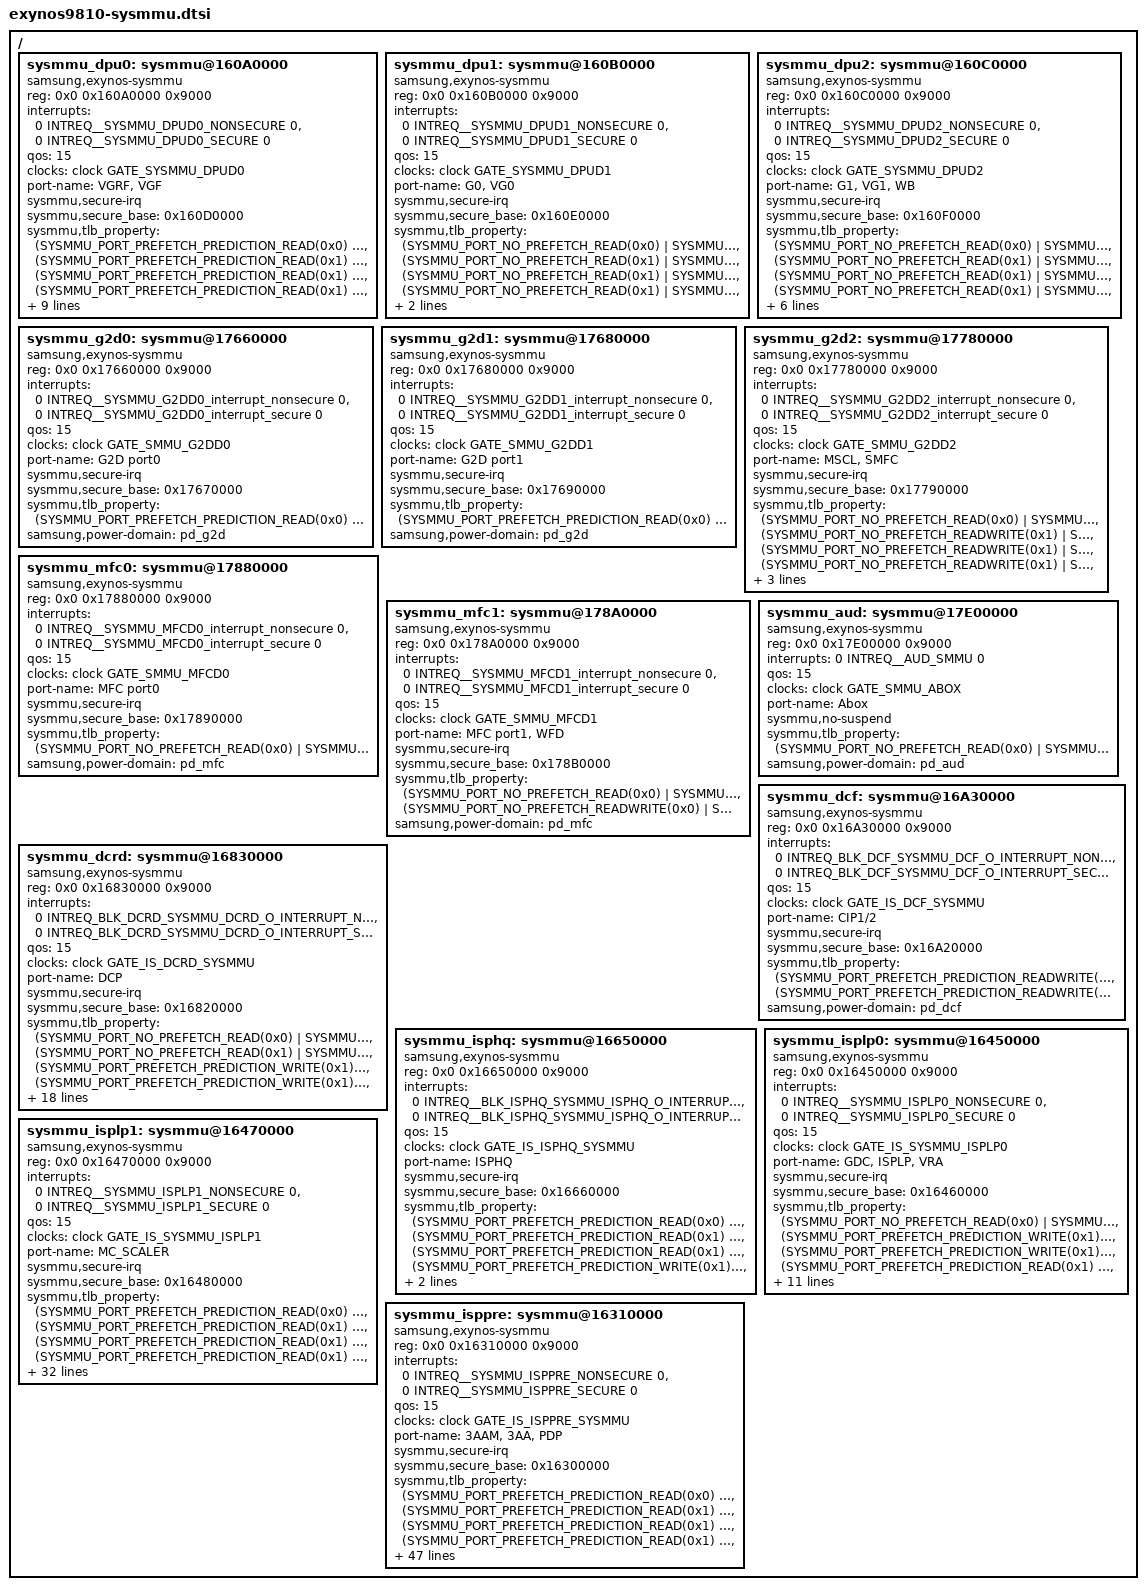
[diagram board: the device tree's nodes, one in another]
/*
 * SAMSUNG EXYNOS9810 SoC device tree source
 *
 * Copyright (c) 2018 Samsung Electronics Co., Ltd.
 *		http://www.samsung.com
 *
 * SAMSUNG EXYNOS9810 SoC device nodes are listed in this file.
 * EXYNOS9810 based board files can include this file and provide
 * values for board specfic bindings.
 *
 * This program is free software; you can redistribute it and/or modify
 * it under the terms of the GNU General Public License version 2 as
 * published by the Free Software Foundation.
 */

#include <dt-bindings/clock/exynos9810.h>
#include <dt-bindings/interrupt-controller/arm-gic.h>
#include <dt-bindings/sysmmu/sysmmu.h>

/ {
	sysmmu_dpu0: sysmmu@160A0000 {
		compatible = "samsung,exynos-sysmmu";
		reg = <0x0 0x160A0000 0x9000>;
		interrupts = <0 INTREQ__SYSMMU_DPUD0_NONSECURE 0>,
			     <0 INTREQ__SYSMMU_DPUD0_SECURE 0>;
		qos = <15>;
		clock-names = "aclk";
		clocks = <&clock GATE_SYSMMU_DPUD0>;
		port-name = "VGRF, VGF";
		sysmmu,secure-irq;
		sysmmu,secure_base = <0x160D0000>;
		sysmmu,tlb_property =
			<(SYSMMU_PORT_PREFETCH_PREDICTION_READ(0x0) | SYSMMU_BL4) SYSMMU_NOID>,
			<(SYSMMU_PORT_PREFETCH_PREDICTION_READ(0x1) | SYSMMU_BL4) SYSMMU_ID_MASK(0x5, 0xF)>,
			<(SYSMMU_PORT_PREFETCH_PREDICTION_READ(0x1) | SYSMMU_BL4) SYSMMU_ID_MASK(0x6, 0xF)>,
			<(SYSMMU_PORT_PREFETCH_PREDICTION_READ(0x1) | SYSMMU_BL4) SYSMMU_ID_MASK(0x7, 0xF)>,
			<(SYSMMU_PORT_PREFETCH_PREDICTION_READ(0x1) | SYSMMU_BL4) SYSMMU_ID_MASK(0xC, 0xF)>,
			<(SYSMMU_PORT_PREFETCH_PREDICTION_READ(0x1) | SYSMMU_BL4) SYSMMU_ID_MASK(0xD, 0xF)>,
			<(SYSMMU_PORT_PREFETCH_PREDICTION_READ(0x1) | SYSMMU_BL4) SYSMMU_ID_MASK(0x0, 0xF)>,
			<(SYSMMU_PORT_PREFETCH_PREDICTION_READ(0x1) | SYSMMU_BL4) SYSMMU_ID_MASK(0x1, 0xF)>,
			<(SYSMMU_PORT_PREFETCH_PREDICTION_READ(0x1) | SYSMMU_BL4) SYSMMU_ID_MASK(0x2, 0xF)>,
			<(SYSMMU_PORT_PREFETCH_PREDICTION_READ(0x1) | SYSMMU_BL4) SYSMMU_ID_MASK(0x3, 0xF)>,
			<(SYSMMU_PORT_PREFETCH_PREDICTION_READ(0x1) | SYSMMU_BL4) SYSMMU_ID_MASK(0x8, 0xF)>,
			<(SYSMMU_PORT_PREFETCH_PREDICTION_READ(0x1) | SYSMMU_BL4) SYSMMU_ID_MASK(0x9, 0xF)>;
		#iommu-cells = <0>;
		samsung,power-domain = <&pd_dpu>;
	};

	sysmmu_dpu1: sysmmu@160B0000 {
		compatible = "samsung,exynos-sysmmu";
		reg = <0x0 0x160B0000 0x9000>;
		interrupts = <0 INTREQ__SYSMMU_DPUD1_NONSECURE 0>,
			     <0 INTREQ__SYSMMU_DPUD1_SECURE 0>;
		qos = <15>;
		clock-names = "aclk";
		clocks = <&clock GATE_SYSMMU_DPUD1>;
		port-name = "G0, VG0";
		sysmmu,secure-irq;
		sysmmu,secure_base = <0x160E0000>;
		sysmmu,tlb_property =
			<(SYSMMU_PORT_NO_PREFETCH_READ(0x0) | SYSMMU_BL1) SYSMMU_NOID>,
			<(SYSMMU_PORT_NO_PREFETCH_READ(0x1) | SYSMMU_BL1) SYSMMU_ID_MASK(0x2, 0xF)>,
			<(SYSMMU_PORT_NO_PREFETCH_READ(0x1) | SYSMMU_BL1) SYSMMU_ID_MASK(0x3, 0xF)>,
			<(SYSMMU_PORT_NO_PREFETCH_READ(0x1) | SYSMMU_BL1) SYSMMU_ID_MASK(0x4, 0xF)>,
			<(SYSMMU_PORT_NO_PREFETCH_READ(0x1) | SYSMMU_BL1) SYSMMU_ID_MASK(0x5, 0xF)>;
		#iommu-cells = <0>;
		samsung,power-domain = <&pd_dpu>;
	};

	sysmmu_dpu2: sysmmu@160C0000 {
		compatible = "samsung,exynos-sysmmu";
		reg = <0x0 0x160C0000 0x9000>;
		interrupts = <0 INTREQ__SYSMMU_DPUD2_NONSECURE 0>,
			     <0 INTREQ__SYSMMU_DPUD2_SECURE 0>;
		qos = <15>;
		clock-names = "aclk";
		clocks = <&clock GATE_SYSMMU_DPUD2>;
		port-name = "G1, VG1, WB";
		sysmmu,secure-irq;
		sysmmu,secure_base = <0x160F0000>;
		sysmmu,tlb_property =
			<(SYSMMU_PORT_NO_PREFETCH_READ(0x0)  | SYSMMU_BL1) SYSMMU_NOID>,
			<(SYSMMU_PORT_NO_PREFETCH_READ(0x1)  | SYSMMU_BL1) SYSMMU_ID_MASK(0x2, 0xF)>,
			<(SYSMMU_PORT_NO_PREFETCH_READ(0x1)  | SYSMMU_BL1) SYSMMU_ID_MASK(0x3, 0xF)>,
			<(SYSMMU_PORT_NO_PREFETCH_READ(0x1)  | SYSMMU_BL1) SYSMMU_ID_MASK(0x4, 0xF)>,
			<(SYSMMU_PORT_NO_PREFETCH_READ(0x1)  | SYSMMU_BL1) SYSMMU_ID_MASK(0x5, 0xF)>,
			<(SYSMMU_PORT_NO_PREFETCH_WRITE(0x1) | SYSMMU_BL1) SYSMMU_ID_MASK(0x0, 0x18)>,
			<(SYSMMU_PORT_NO_PREFETCH_WRITE(0x1) | SYSMMU_BL1) SYSMMU_ID_MASK(0x8, 0x18)>,
			<(SYSMMU_PORT_NO_PREFETCH_WRITE(0x1) | SYSMMU_BL1) SYSMMU_ID_MASK(0x10, 0x18)>,
			<(SYSMMU_PORT_NO_PREFETCH_WRITE(0x1) | SYSMMU_BL1) SYSMMU_ID_MASK(0x18, 0x18)>;
		#iommu-cells = <0>;
		samsung,power-domain = <&pd_dpu>;
	};

	sysmmu_g2d0: sysmmu@17660000 {
		compatible = "samsung,exynos-sysmmu";
		reg = <0x0 0x17660000 0x9000>;
		interrupts = <0 INTREQ__SYSMMU_G2DD0_interrupt_nonsecure 0>,
			     <0 INTREQ__SYSMMU_G2DD0_interrupt_secure 0>;
		qos = <15>;
		clock-names = "aclk";
		clocks = <&clock GATE_SMMU_G2DD0>;
		port-name = "G2D port0";
		sysmmu,secure-irq;
		sysmmu,secure_base = <0x17670000>;
		sysmmu,tlb_property =
			<(SYSMMU_PORT_PREFETCH_PREDICTION_READ(0x0) | SYSMMU_BL32) SYSMMU_NOID>;
		#iommu-cells = <0>;
		samsung,power-domain = <&pd_g2d>;
	};

	sysmmu_g2d1: sysmmu@17680000 {
		compatible = "samsung,exynos-sysmmu";
		reg = <0x0 0x17680000 0x9000>;
		interrupts = <0 INTREQ__SYSMMU_G2DD1_interrupt_nonsecure 0>,
			     <0 INTREQ__SYSMMU_G2DD1_interrupt_secure 0>;
		qos = <15>;
		clock-names = "aclk";
		clocks = <&clock GATE_SMMU_G2DD1>;
		port-name = "G2D port1";
		sysmmu,secure-irq;
		sysmmu,secure_base = <0x17690000>;
		sysmmu,tlb_property =
			<(SYSMMU_PORT_PREFETCH_PREDICTION_READ(0x0) | SYSMMU_BL32) SYSMMU_NOID>;
		#iommu-cells = <0>;
		samsung,power-domain = <&pd_g2d>;
	};

	sysmmu_g2d2: sysmmu@17780000 {
		compatible = "samsung,exynos-sysmmu";
		reg = <0x0 0x17780000 0x9000>;
		interrupts = <0 INTREQ__SYSMMU_G2DD2_interrupt_nonsecure 0>,
			     <0 INTREQ__SYSMMU_G2DD2_interrupt_secure 0>;
		qos = <15>;
		clock-names = "aclk";
		clocks = <&clock GATE_SMMU_G2DD2>;
		port-name = "MSCL, SMFC";
		sysmmu,secure-irq;
		sysmmu,secure_base = <0x17790000>;
		sysmmu,tlb_property =
			<(SYSMMU_PORT_NO_PREFETCH_READ(0x0)      | SYSMMU_BL32) SYSMMU_NOID>,
			<(SYSMMU_PORT_NO_PREFETCH_READWRITE(0x1) | SYSMMU_BL32) SYSMMU_ID_MASK(0x0, 0x3)>,
			<(SYSMMU_PORT_NO_PREFETCH_READWRITE(0x1) | SYSMMU_BL32) SYSMMU_ID_MASK(0x0, 0x3)>,
			<(SYSMMU_PORT_NO_PREFETCH_READWRITE(0x1) | SYSMMU_BL32) SYSMMU_ID_MASK(0x0, 0x3)>,
			<(SYSMMU_PORT_NO_PREFETCH_READWRITE(0x1) | SYSMMU_BL32) SYSMMU_ID_MASK(0x0, 0x3)>,
			<(SYSMMU_PORT_NO_PREFETCH_READWRITE(0x1) | SYSMMU_BL2)  SYSMMU_ID_MASK(0x2, 0x3)>;
		#iommu-cells = <0>;
		samsung,power-domain = <&pd_g2d>;
	};

	sysmmu_mfc0: sysmmu@17880000 {
		compatible = "samsung,exynos-sysmmu";
		reg = <0x0 0x17880000 0x9000>;
		interrupts = <0 INTREQ__SYSMMU_MFCD0_interrupt_nonsecure 0>,
			     <0 INTREQ__SYSMMU_MFCD0_interrupt_secure 0>;
		qos = <15>;
		clock-names = "aclk";
		clocks = <&clock GATE_SMMU_MFCD0>;
		port-name = "MFC port0";
		sysmmu,secure-irq;
		sysmmu,secure_base = <0x17890000>;
		sysmmu,tlb_property =
			<(SYSMMU_PORT_NO_PREFETCH_READ(0x0) | SYSMMU_BL8) SYSMMU_NOID>;
		#iommu-cells = <0>;
		samsung,power-domain = <&pd_mfc>;
	};

	sysmmu_mfc1: sysmmu@178A0000 {
		compatible = "samsung,exynos-sysmmu";
		reg = <0x0 0x178A0000 0x9000>;
		interrupts = <0 INTREQ__SYSMMU_MFCD1_interrupt_nonsecure 0>,
			     <0 INTREQ__SYSMMU_MFCD1_interrupt_secure 0>;
		qos = <15>;
		clock-names = "aclk";
		clocks = <&clock GATE_SMMU_MFCD1>;
		port-name = "MFC port1, WFD";
		sysmmu,secure-irq;
		sysmmu,secure_base = <0x178B0000>;
		sysmmu,tlb_property =
			<(SYSMMU_PORT_NO_PREFETCH_READ(0x0)      | SYSMMU_BL8) SYSMMU_NOID>,
			<(SYSMMU_PORT_NO_PREFETCH_READWRITE(0x0) | SYSMMU_BL2) SYSMMU_ID_MASK(0x1, 0x1)>;
		#iommu-cells = <0>;
		samsung,power-domain = <&pd_mfc>;
	};

	sysmmu_aud: sysmmu@17E00000 {
		compatible = "samsung,exynos-sysmmu";
		reg = <0x0 0x17E00000 0x9000>;
		interrupts = <0 INTREQ__AUD_SMMU 0>;
		qos = <15>;
		clock-names = "aclk";
		clocks = <&clock GATE_SMMU_ABOX>;
		port-name = "Abox";
		sysmmu,no-suspend;
		sysmmu,tlb_property =
			<(SYSMMU_PORT_NO_PREFETCH_READ(0x0) | SYSMMU_BL1) SYSMMU_NOID>;
		#iommu-cells = <0>;
		samsung,power-domain = <&pd_aud>;
	};

	sysmmu_dcf: sysmmu@16A30000 {
		compatible = "samsung,exynos-sysmmu";
		reg = <0x0 0x16A30000 0x9000>;
		interrupts = <0 INTREQ_BLK_DCF_SYSMMU_DCF_O_INTERRUPT_NONSECURE 0>,
			     <0 INTREQ_BLK_DCF_SYSMMU_DCF_O_INTERRUPT_SECURE 0>;
		qos = <15>;
		clock-names = "aclk";
		clocks = <&clock GATE_IS_DCF_SYSMMU>;
		port-name = "CIP1/2";
		sysmmu,secure-irq;
		sysmmu,secure_base = <0x16A20000>;
		sysmmu,tlb_property =
			<(SYSMMU_PORT_PREFETCH_PREDICTION_READWRITE(0x0) | SYSMMU_BL1) SYSMMU_NOID>,
			<(SYSMMU_PORT_PREFETCH_PREDICTION_READWRITE(0x1) | SYSMMU_BL1) SYSMMU_ID_MASK(0x1, 0x1)>;
		#iommu-cells = <0>;
		samsung,power-domain = <&pd_dcf>;
	};

	sysmmu_dcrd: sysmmu@16830000 {
		compatible = "samsung,exynos-sysmmu";
		reg = <0x0 0x16830000 0x9000>;
		interrupts = <0 INTREQ_BLK_DCRD_SYSMMU_DCRD_O_INTERRUPT_NONSECURE 0>,
			     <0 INTREQ_BLK_DCRD_SYSMMU_DCRD_O_INTERRUPT_SECURE 0>;
		qos = <15>;
		clock-names = "aclk";
		clocks = <&clock GATE_IS_DCRD_SYSMMU>;
		port-name = "DCP";
		sysmmu,secure-irq;
		sysmmu,secure_base = <0x16820000>;
		sysmmu,tlb_property =
			<(SYSMMU_PORT_NO_PREFETCH_READ(0x0) | SYSMMU_BL32) SYSMMU_NOID>,
			<(SYSMMU_PORT_NO_PREFETCH_READ(0x1) | SYSMMU_BL32) SYSMMU_ID_MASK(0x1, 0x1F)>,
			<(SYSMMU_PORT_PREFETCH_PREDICTION_WRITE(0x1) | SYSMMU_BL1) SYSMMU_ID_MASK(0x0, 0x1F)>,
			<(SYSMMU_PORT_PREFETCH_PREDICTION_WRITE(0x1) | SYSMMU_BL1) SYSMMU_ID_MASK(0x1, 0x1F)>,
			<(SYSMMU_PORT_PREFETCH_PREDICTION_WRITE(0x1) | SYSMMU_BL1) SYSMMU_ID_MASK(0x2, 0x1F)>,
			<(SYSMMU_PORT_PREFETCH_PREDICTION_WRITE(0x1) | SYSMMU_BL1) SYSMMU_ID_MASK(0x3, 0x1F)>,
			<(SYSMMU_PORT_PREFETCH_PREDICTION_WRITE(0x1) | SYSMMU_BL1) SYSMMU_ID_MASK(0x4, 0x1F)>,
			<(SYSMMU_PORT_PREFETCH_PREDICTION_WRITE(0x1) | SYSMMU_BL1) SYSMMU_ID_MASK(0x5, 0x1F)>,
			<(SYSMMU_PORT_PREFETCH_PREDICTION_WRITE(0x1) | SYSMMU_BL1) SYSMMU_ID_MASK(0x6, 0x1F)>,
			<(SYSMMU_PORT_PREFETCH_PREDICTION_WRITE(0x1) | SYSMMU_BL1) SYSMMU_ID_MASK(0x7, 0x1F)>,
			<(SYSMMU_PORT_PREFETCH_PREDICTION_WRITE(0x1) | SYSMMU_BL1) SYSMMU_ID_MASK(0x8, 0x1F)>,
			<(SYSMMU_PORT_PREFETCH_PREDICTION_WRITE(0x1) | SYSMMU_BL1) SYSMMU_ID_MASK(0x9, 0x1F)>,
			<(SYSMMU_PORT_PREFETCH_PREDICTION_WRITE(0x1) | SYSMMU_BL1) SYSMMU_ID_MASK(0xA, 0x1F)>,
			<(SYSMMU_PORT_PREFETCH_PREDICTION_WRITE(0x1) | SYSMMU_BL1) SYSMMU_ID_MASK(0xB, 0x1F)>,
			<(SYSMMU_PORT_PREFETCH_PREDICTION_WRITE(0x1) | SYSMMU_BL1) SYSMMU_ID_MASK(0xC, 0x1F)>,
			<(SYSMMU_PORT_PREFETCH_PREDICTION_READ(0x1)  | SYSMMU_BL1) SYSMMU_ID_MASK(0x2, 0x1F)>,
			<(SYSMMU_PORT_PREFETCH_PREDICTION_READ(0x1)  | SYSMMU_BL1) SYSMMU_ID_MASK(0x3, 0x1F)>,
			<(SYSMMU_PORT_PREFETCH_PREDICTION_READ(0x1)  | SYSMMU_BL1) SYSMMU_ID_MASK(0x4, 0x1F)>,
			<(SYSMMU_PORT_PREFETCH_PREDICTION_READ(0x1)  | SYSMMU_BL1) SYSMMU_ID_MASK(0x5, 0x1F)>,
			<(SYSMMU_PORT_PREFETCH_PREDICTION_WRITE(0x1) | SYSMMU_BL1) SYSMMU_ID_MASK(0xD, 0x1F)>,
			<(SYSMMU_PORT_PREFETCH_PREDICTION_WRITE(0x1) | SYSMMU_BL1) SYSMMU_ID_MASK(0xE, 0x1F)>;
		#iommu-cells = <0>;
		samsung,power-domain = <&pd_dcrd>;
	};

	sysmmu_isphq: sysmmu@16650000 {
		compatible = "samsung,exynos-sysmmu";
		reg = <0x0 0x16650000 0x9000>;
		interrupts = <0 INTREQ__BLK_ISPHQ_SYSMMU_ISPHQ_O_INTERRUPT_NONSECURE 0>,
			     <0 INTREQ__BLK_ISPHQ_SYSMMU_ISPHQ_O_INTERRUPT_SECURE 0>;
		qos = <15>;
		clock-names = "aclk";
		clocks = <&clock GATE_IS_ISPHQ_SYSMMU>;
		port-name = "ISPHQ";
		sysmmu,secure-irq;
		sysmmu,secure_base = <0x16660000>;
		sysmmu,tlb_property =
			<(SYSMMU_PORT_PREFETCH_PREDICTION_READ(0x0)  | SYSMMU_BL16) SYSMMU_NOID>,
			<(SYSMMU_PORT_PREFETCH_PREDICTION_READ(0x1)  | SYSMMU_BL16) SYSMMU_ID_MASK(0x1, 0xF)>,
			<(SYSMMU_PORT_PREFETCH_PREDICTION_READ(0x1)  | SYSMMU_BL16) SYSMMU_ID_MASK(0x2, 0xF)>,
			<(SYSMMU_PORT_PREFETCH_PREDICTION_WRITE(0x1) | SYSMMU_BL16) SYSMMU_ID_MASK(0x0, 0xF)>,
			<(SYSMMU_PORT_PREFETCH_PREDICTION_WRITE(0x1) | SYSMMU_BL16) SYSMMU_ID_MASK(0x1, 0xF)>;
		#iommu-cells = <0>;
		samsung,power-domain = <&pd_isphq>;
	};

	sysmmu_isplp0: sysmmu@16450000 {
		compatible = "samsung,exynos-sysmmu";
		reg = <0x0 0x16450000 0x9000>;
		interrupts = <0 INTREQ__SYSMMU_ISPLP0_NONSECURE 0>,
			     <0 INTREQ__SYSMMU_ISPLP0_SECURE 0>;
		qos = <15>;
		clock-names = "aclk";
		clocks = <&clock GATE_IS_SYSMMU_ISPLP0>;
		port-name = "GDC, ISPLP, VRA";
		sysmmu,secure-irq;
		sysmmu,secure_base = <0x16460000>;
		sysmmu,tlb_property =
			/* GDC */
			<(SYSMMU_PORT_NO_PREFETCH_READ(0x0)          | SYSMMU_BL16) SYSMMU_NOID>,
			<(SYSMMU_PORT_PREFETCH_PREDICTION_WRITE(0x1) | SYSMMU_BL32) SYSMMU_ID_MASK(0x1, 0xF)>,
			<(SYSMMU_PORT_PREFETCH_PREDICTION_WRITE(0x1) | SYSMMU_BL32) SYSMMU_ID_MASK(0x5, 0xF)>,
			/* ISPLP */
			<(SYSMMU_PORT_PREFETCH_PREDICTION_READ(0x1)  | SYSMMU_BL1) SYSMMU_ID_MASK(0x0, 0x3F)>,
			<(SYSMMU_PORT_PREFETCH_PREDICTION_READ(0x1)  | SYSMMU_BL1) SYSMMU_ID_MASK(0x4, 0x3F)>,
			<(SYSMMU_PORT_PREFETCH_PREDICTION_READ(0x1)  | SYSMMU_BL1) SYSMMU_ID_MASK(0x8, 0x3F)>,
			<(SYSMMU_PORT_PREFETCH_PREDICTION_READ(0x1)  | SYSMMU_BL1) SYSMMU_ID_MASK(0xC, 0x3F)>,
			<(SYSMMU_PORT_PREFETCH_PREDICTION_WRITE(0x1) | SYSMMU_BL1) SYSMMU_ID_MASK(0x0, 0x3F)>,
			<(SYSMMU_PORT_PREFETCH_PREDICTION_WRITE(0x1) | SYSMMU_BL1) SYSMMU_ID_MASK(0x4, 0x3F)>,
			<(SYSMMU_PORT_PREFETCH_PREDICTION_WRITE(0x1) | SYSMMU_BL1) SYSMMU_ID_MASK(0x8, 0x3F)>,
			<(SYSMMU_PORT_PREFETCH_PREDICTION_WRITE(0x1) | SYSMMU_BL1) SYSMMU_ID_MASK(0xC, 0x3F)>,
			<(SYSMMU_PORT_PREFETCH_PREDICTION_WRITE(0x1) | SYSMMU_BL1) SYSMMU_ID_MASK(0x10, 0x3F)>,
			/* VRA */
			<(SYSMMU_PORT_PREFETCH_PREDICTION_READ(0x1)  | SYSMMU_BL1) SYSMMU_ID_MASK(0x2, 0x3)>,
			<(SYSMMU_PORT_PREFETCH_PREDICTION_WRITE(0x1) | SYSMMU_BL1) SYSMMU_ID_MASK(0x2, 0x3)>;
		#iommu-cells = <0>;
		samsung,power-domain = <&pd_isplp>;
	};

	sysmmu_isplp1: sysmmu@16470000 {
		compatible = "samsung,exynos-sysmmu";
		reg = <0x0 0x16470000 0x9000>;
		interrupts = <0 INTREQ__SYSMMU_ISPLP1_NONSECURE 0>,
			     <0 INTREQ__SYSMMU_ISPLP1_SECURE 0>;
		qos = <15>;
		clock-names = "aclk";
		clocks = <&clock GATE_IS_SYSMMU_ISPLP1>;
		port-name = "MC_SCALER";
		sysmmu,secure-irq;
		sysmmu,secure_base = <0x16480000>;
		sysmmu,tlb_property =
			/* RDMA0 */
			<(SYSMMU_PORT_PREFETCH_PREDICTION_READ(0x0) | SYSMMU_BL1) SYSMMU_NOID>,
			<(SYSMMU_PORT_PREFETCH_PREDICTION_READ(0x1) | SYSMMU_BL1) SYSMMU_ID_MASK(0x1, 0x3F)>,
			<(SYSMMU_PORT_PREFETCH_PREDICTION_READ(0x1) | SYSMMU_BL1) SYSMMU_ID_MASK(0x2, 0x3F)>,
			/* RDMA0 (2bit) */
			<(SYSMMU_PORT_PREFETCH_PREDICTION_READ(0x1) | SYSMMU_BL1) SYSMMU_ID_MASK(0x6, 0x3F)>,
			<(SYSMMU_PORT_PREFETCH_PREDICTION_READ(0x1) | SYSMMU_BL1) SYSMMU_ID_MASK(0x7, 0x3F)>,
			/* WDMA0 */
			<(SYSMMU_PORT_PREFETCH_PREDICTION_WRITE(0x1) | SYSMMU_BL1) SYSMMU_ID_MASK(0x0, 0x3F)>,
			<(SYSMMU_PORT_PREFETCH_PREDICTION_WRITE(0x1) | SYSMMU_BL1) SYSMMU_ID_MASK(0x1, 0x3F)>,
			<(SYSMMU_PORT_PREFETCH_PREDICTION_WRITE(0x1) | SYSMMU_BL1) SYSMMU_ID_MASK(0x2, 0x3F)>,
			/* WDMA1 */
			<(SYSMMU_PORT_PREFETCH_PREDICTION_WRITE(0x1) | SYSMMU_BL1) SYSMMU_ID_MASK(0x3, 0x3F)>,
			<(SYSMMU_PORT_PREFETCH_PREDICTION_WRITE(0x1) | SYSMMU_BL1) SYSMMU_ID_MASK(0x4, 0x3F)>,
			<(SYSMMU_PORT_PREFETCH_PREDICTION_WRITE(0x1) | SYSMMU_BL1) SYSMMU_ID_MASK(0x5, 0x3F)>,
			/* WDMA2 */
			<(SYSMMU_PORT_PREFETCH_PREDICTION_WRITE(0x1) | SYSMMU_BL1) SYSMMU_ID_MASK(0x6, 0x3F)>,
			<(SYSMMU_PORT_PREFETCH_PREDICTION_WRITE(0x1) | SYSMMU_BL1) SYSMMU_ID_MASK(0x7, 0x3F)>,
			<(SYSMMU_PORT_PREFETCH_PREDICTION_WRITE(0x1) | SYSMMU_BL1) SYSMMU_ID_MASK(0x8, 0x3F)>,
			/* WDMA3 */
			<(SYSMMU_PORT_PREFETCH_PREDICTION_WRITE(0x1) | SYSMMU_BL1) SYSMMU_ID_MASK(0x9, 0x3F)>,
			<(SYSMMU_PORT_PREFETCH_PREDICTION_WRITE(0x1) | SYSMMU_BL1) SYSMMU_ID_MASK(0xA, 0x3F)>,
			<(SYSMMU_PORT_PREFETCH_PREDICTION_WRITE(0x1) | SYSMMU_BL1) SYSMMU_ID_MASK(0xB, 0x3F)>,
			/* WDMA4 */
			<(SYSMMU_PORT_PREFETCH_PREDICTION_WRITE(0x1) | SYSMMU_BL1) SYSMMU_ID_MASK(0xC, 0x3F)>,
			<(SYSMMU_PORT_PREFETCH_PREDICTION_WRITE(0x1) | SYSMMU_BL1) SYSMMU_ID_MASK(0xD, 0x3F)>,
			<(SYSMMU_PORT_PREFETCH_PREDICTION_WRITE(0x1) | SYSMMU_BL1) SYSMMU_ID_MASK(0xE, 0x3F)>,
			/* WDMA5 */
			<(SYSMMU_PORT_PREFETCH_PREDICTION_WRITE(0x1) | SYSMMU_BL1) SYSMMU_ID_MASK(0xF, 0x3F)>,
			<(SYSMMU_PORT_PREFETCH_PREDICTION_WRITE(0x1) | SYSMMU_BL1) SYSMMU_ID_MASK(0x10, 0x3F)>,
			<(SYSMMU_PORT_PREFETCH_PREDICTION_WRITE(0x1) | SYSMMU_BL1) SYSMMU_ID_MASK(0x11, 0x3F)>,
			/* WDMA0 (2bit) */
			<(SYSMMU_PORT_PREFETCH_PREDICTION_WRITE(0x1) | SYSMMU_BL1) SYSMMU_ID_MASK(0x15, 0x3F)>,
			<(SYSMMU_PORT_PREFETCH_PREDICTION_WRITE(0x1) | SYSMMU_BL1) SYSMMU_ID_MASK(0x16, 0x3F)>,
			/* WDMA1 (2bit) */
			<(SYSMMU_PORT_PREFETCH_PREDICTION_WRITE(0x1) | SYSMMU_BL1) SYSMMU_ID_MASK(0x17, 0x3F)>,
			<(SYSMMU_PORT_PREFETCH_PREDICTION_WRITE(0x1) | SYSMMU_BL1) SYSMMU_ID_MASK(0x18, 0x3F)>,
			/* WDMA2 (2bit) */
			<(SYSMMU_PORT_PREFETCH_PREDICTION_WRITE(0x1) | SYSMMU_BL1) SYSMMU_ID_MASK(0x19, 0x3F)>,
			<(SYSMMU_PORT_PREFETCH_PREDICTION_WRITE(0x1) | SYSMMU_BL1) SYSMMU_ID_MASK(0x1A, 0x3F)>,
			/* WDMA3 (2bit) */
			<(SYSMMU_PORT_PREFETCH_PREDICTION_WRITE(0x1) | SYSMMU_BL1) SYSMMU_ID_MASK(0x1B, 0x3F)>,
			<(SYSMMU_PORT_PREFETCH_PREDICTION_WRITE(0x1) | SYSMMU_BL1) SYSMMU_ID_MASK(0x1C, 0x3F)>,
			/* WDMA4 (2bit) */
			<(SYSMMU_PORT_PREFETCH_PREDICTION_WRITE(0x1) | SYSMMU_BL1) SYSMMU_ID_MASK(0x1D, 0x3F)>,
			<(SYSMMU_PORT_PREFETCH_PREDICTION_WRITE(0x1) | SYSMMU_BL1) SYSMMU_ID_MASK(0x1E, 0x3F)>,
			/* WDMA5 (2bit) */
			<(SYSMMU_PORT_PREFETCH_PREDICTION_WRITE(0x1) | SYSMMU_BL1) SYSMMU_ID_MASK(0x1F, 0x3F)>,
			<(SYSMMU_PORT_PREFETCH_PREDICTION_WRITE(0x1) | SYSMMU_BL1) SYSMMU_ID_MASK(0x20, 0x3F)>;
		#iommu-cells = <0>;
		samsung,power-domain = <&pd_isplp>;
	};

	sysmmu_isppre: sysmmu@16310000 {
		compatible = "samsung,exynos-sysmmu";
		reg = <0x0 0x16310000 0x9000>;
		interrupts = <0 INTREQ__SYSMMU_ISPPRE_NONSECURE 0>,
			     <0 INTREQ__SYSMMU_ISPPRE_SECURE 0>;
		qos = <15>;
		clock-names = "aclk";
		clocks = <&clock GATE_IS_ISPPRE_SYSMMU>;
		port-name = "3AAM, 3AA, PDP";
		sysmmu,secure-irq;
		sysmmu,secure_base = <0x16300000>;
		sysmmu,tlb_property =
			/* 3AA0 */
			<(SYSMMU_PORT_PREFETCH_PREDICTION_READ(0x0)  | SYSMMU_BL1) SYSMMU_NOID>,
			<(SYSMMU_PORT_PREFETCH_PREDICTION_READ(0x1)  | SYSMMU_BL1) SYSMMU_ID_MASK(0x6, 0x7F)>,
			<(SYSMMU_PORT_PREFETCH_PREDICTION_READ(0x1)  | SYSMMU_BL1) SYSMMU_ID_MASK(0xA, 0x7F)>,
			<(SYSMMU_PORT_PREFETCH_PREDICTION_READ(0x1)  | SYSMMU_BL1) SYSMMU_ID_MASK(0xE, 0x7F)>,
			<(SYSMMU_PORT_PREFETCH_PREDICTION_READ(0x1)  | SYSMMU_BL1) SYSMMU_ID_MASK(0x12, 0x7F)>,
			<(SYSMMU_PORT_PREFETCH_PREDICTION_WRITE(0x1) | SYSMMU_BL1) SYSMMU_ID_MASK(0x2, 0x7F)>,
			<(SYSMMU_PORT_PREFETCH_PREDICTION_WRITE(0x1) | SYSMMU_BL1) SYSMMU_ID_MASK(0x6, 0x7F)>,
			<(SYSMMU_PORT_PREFETCH_PREDICTION_WRITE(0x1) | SYSMMU_BL1) SYSMMU_ID_MASK(0xA, 0x7F)>,
			<(SYSMMU_PORT_PREFETCH_PREDICTION_WRITE(0x1) | SYSMMU_BL1) SYSMMU_ID_MASK(0xE, 0x7F)>,
			<(SYSMMU_PORT_PREFETCH_PREDICTION_WRITE(0x1) | SYSMMU_BL1) SYSMMU_ID_MASK(0x12, 0x7F)>,
			<(SYSMMU_PORT_PREFETCH_PREDICTION_WRITE(0x1) | SYSMMU_BL1) SYSMMU_ID_MASK(0x16, 0x7F)>,
			<(SYSMMU_PORT_PREFETCH_PREDICTION_WRITE(0x1) | SYSMMU_BL1) SYSMMU_ID_MASK(0x1A, 0x7F)>,
			<(SYSMMU_PORT_PREFETCH_PREDICTION_WRITE(0x1) | SYSMMU_BL1) SYSMMU_ID_MASK(0x1E, 0x7F)>,
			<(SYSMMU_PORT_PREFETCH_PREDICTION_WRITE(0x1) | SYSMMU_BL1) SYSMMU_ID_MASK(0x22, 0x7F)>,
			<(SYSMMU_PORT_PREFETCH_PREDICTION_WRITE(0x1) | SYSMMU_BL1) SYSMMU_ID_MASK(0x26, 0x7F)>,
			/* 3AA1 */
			<(SYSMMU_PORT_PREFETCH_PREDICTION_READ(0x1)  | SYSMMU_BL1) SYSMMU_ID_MASK(0x3, 0x7F)>,
			<(SYSMMU_PORT_PREFETCH_PREDICTION_READ(0x1)  | SYSMMU_BL1) SYSMMU_ID_MASK(0x7, 0x7F)>,
			<(SYSMMU_PORT_PREFETCH_PREDICTION_READ(0x1)  | SYSMMU_BL1) SYSMMU_ID_MASK(0xB, 0x7F)>,
			<(SYSMMU_PORT_PREFETCH_PREDICTION_READ(0x1)  | SYSMMU_BL1) SYSMMU_ID_MASK(0xF, 0x7F)>,
			<(SYSMMU_PORT_PREFETCH_PREDICTION_READ(0x1)  | SYSMMU_BL1) SYSMMU_ID_MASK(0x13, 0x7F)>,
			<(SYSMMU_PORT_PREFETCH_PREDICTION_WRITE(0x1) | SYSMMU_BL1) SYSMMU_ID_MASK(0x3, 0x7F)>,
			<(SYSMMU_PORT_PREFETCH_PREDICTION_WRITE(0x1) | SYSMMU_BL1) SYSMMU_ID_MASK(0x7, 0x7F)>,
			<(SYSMMU_PORT_PREFETCH_PREDICTION_WRITE(0x1) | SYSMMU_BL1) SYSMMU_ID_MASK(0xB, 0x7F)>,
			<(SYSMMU_PORT_PREFETCH_PREDICTION_WRITE(0x1) | SYSMMU_BL1) SYSMMU_ID_MASK(0xF, 0x7F)>,
			<(SYSMMU_PORT_PREFETCH_PREDICTION_WRITE(0x1) | SYSMMU_BL1) SYSMMU_ID_MASK(0x13, 0x7F)>,
			<(SYSMMU_PORT_PREFETCH_PREDICTION_WRITE(0x1) | SYSMMU_BL1) SYSMMU_ID_MASK(0x17, 0x7F)>,
			<(SYSMMU_PORT_PREFETCH_PREDICTION_WRITE(0x1) | SYSMMU_BL1) SYSMMU_ID_MASK(0x1B, 0x7F)>,
			<(SYSMMU_PORT_PREFETCH_PREDICTION_WRITE(0x1) | SYSMMU_BL1) SYSMMU_ID_MASK(0x1F, 0x7F)>,
			<(SYSMMU_PORT_PREFETCH_PREDICTION_WRITE(0x1) | SYSMMU_BL1) SYSMMU_ID_MASK(0x23, 0x7F)>,
			<(SYSMMU_PORT_PREFETCH_PREDICTION_WRITE(0x1) | SYSMMU_BL1) SYSMMU_ID_MASK(0x27, 0x7F)>,
			/* PDP */
			<(SYSMMU_PORT_PREFETCH_PREDICTION_WRITE(0x1) | SYSMMU_BL1) SYSMMU_ID_MASK(0x0, 0x7F)>,
			<(SYSMMU_PORT_PREFETCH_PREDICTION_WRITE(0x1) | SYSMMU_BL1) SYSMMU_ID_MASK(0x4, 0x7F)>,
			<(SYSMMU_PORT_PREFETCH_PREDICTION_WRITE(0x1) | SYSMMU_BL1) SYSMMU_ID_MASK(0x8, 0x7F)>,
			<(SYSMMU_PORT_PREFETCH_PREDICTION_WRITE(0x1) | SYSMMU_BL1) SYSMMU_ID_MASK(0xC, 0x7F)>,
			<(SYSMMU_PORT_PREFETCH_PREDICTION_WRITE(0x1) | SYSMMU_BL1) SYSMMU_ID_MASK(0x10, 0x7F)>,
			<(SYSMMU_PORT_PREFETCH_PREDICTION_WRITE(0x1) | SYSMMU_BL1) SYSMMU_ID_MASK(0x14, 0x7F)>,
			<(SYSMMU_PORT_PREFETCH_PREDICTION_WRITE(0x1) | SYSMMU_BL1) SYSMMU_ID_MASK(0x18, 0x7F)>,
			<(SYSMMU_PORT_PREFETCH_PREDICTION_WRITE(0x1) | SYSMMU_BL1) SYSMMU_ID_MASK(0x1C, 0x7F)>,
			<(SYSMMU_PORT_PREFETCH_PREDICTION_WRITE(0x1) | SYSMMU_BL1) SYSMMU_ID_MASK(0x20, 0x7F)>,
			<(SYSMMU_PORT_PREFETCH_PREDICTION_WRITE(0x1) | SYSMMU_BL1) SYSMMU_ID_MASK(0x24, 0x7F)>,
			<(SYSMMU_PORT_PREFETCH_PREDICTION_WRITE(0x1) | SYSMMU_BL1) SYSMMU_ID_MASK(0x28, 0x7F)>,
			<(SYSMMU_PORT_PREFETCH_PREDICTION_WRITE(0x1) | SYSMMU_BL1) SYSMMU_ID_MASK(0x2C, 0x7F)>,
			<(SYSMMU_PORT_PREFETCH_PREDICTION_WRITE(0x1) | SYSMMU_BL1) SYSMMU_ID_MASK(0x30, 0x7F)>,
			<(SYSMMU_PORT_PREFETCH_PREDICTION_WRITE(0x1) | SYSMMU_BL1) SYSMMU_ID_MASK(0x34, 0x7F)>,
			<(SYSMMU_PORT_PREFETCH_PREDICTION_WRITE(0x1) | SYSMMU_BL1) SYSMMU_ID_MASK(0x38, 0x7F)>,
			<(SYSMMU_PORT_PREFETCH_PREDICTION_WRITE(0x1) | SYSMMU_BL1) SYSMMU_ID_MASK(0x3C, 0x7F)>,
			/* PDP stat */
			<(SYSMMU_PORT_PREFETCH_PREDICTION_WRITE(0x1) | SYSMMU_BL1) SYSMMU_ID_MASK(0x1, 0x7F)>,
			<(SYSMMU_PORT_PREFETCH_PREDICTION_WRITE(0x1) | SYSMMU_BL1) SYSMMU_ID_MASK(0x5, 0x7F)>,
			<(SYSMMU_PORT_PREFETCH_PREDICTION_WRITE(0x1) | SYSMMU_BL1) SYSMMU_ID_MASK(0x21, 0x7F)>,
			<(SYSMMU_PORT_PREFETCH_PREDICTION_WRITE(0x1) | SYSMMU_BL1) SYSMMU_ID_MASK(0x25, 0x7F)>;
		#iommu-cells = <0>;
		samsung,power-domain = <&pd_isppre>;
	};
};
